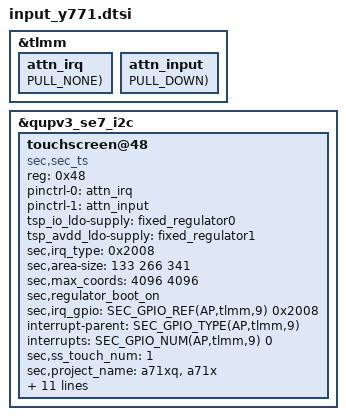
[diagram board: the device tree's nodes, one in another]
&tlmm {
	attn_irq: attn_irq {
		GPIO_CONFIG_PUD(AP,tlmm,9, FUNC_INPUT_WAKEUP, PULL_NONE);
	};

	attn_input: attn_input {
		GPIO_CONFIG_PUD(AP,tlmm,9, FUNC_INPUT, PULL_DOWN);
	};
};

&qupv3_se7_i2c {
	#address-cells = <1>;
	#size-cells = <0>;
	status = "ok";
	touchscreen@48 {
		status = "ok";
		compatible = "sec,sec_ts";
		reg = <0x48>;
		pinctrl-names = "on_state", "off_state";
		pinctrl-0 = <&attn_irq>;
		pinctrl-1 = <&attn_input>;
		tsp_io_ldo-supply = <&fixed_regulator0>;
		tsp_avdd_ldo-supply = <&fixed_regulator1>;
		sec,irq_type = <0x2008>;
		sec,area-size = <133 266 341>; /* indicator: 24dp navigator:48dp edge:60px dpi=320 */
		sec,max_coords = <4096 4096>; /* x y */
		sec,regulator_boot_on;
		sec,irq_gpio = <SEC_GPIO_REF(AP,tlmm,9) 0x2008>;
		interrupt-parent = <SEC_GPIO_TYPE(AP,tlmm,9)>;
		interrupts = <SEC_GPIO_NUM(AP,tlmm,9) 0>;
		sec,ss_touch_num = <1>;

		/* This part is for firmware */
		sec,project_name = "a71xq", "a71x";
		sec,firmware_name = "tsp_sec/y771_a71x.bin";
	};
};

/* /home/dpi/qb5_8814/workspace/P4_1716/android/kernel/kmodule/input/touchscreen/lsi/y771/input-qc-y771.a71xq.dtsi */
&qupv3_se7_i2c {
	touchscreen@48 {
		sec,bringup = <3>;
		sec,tclm_level = <2>;
		sec,afe_base = <0x0108>;
		enable_settings_aot;
		support_ear_detect_mode;
		sync-reportrate-120 = "Y";
		support_fod;
		support_fod_gesture;
		support_open_short_test;
		support_mis_calibration_test;
	};
};
